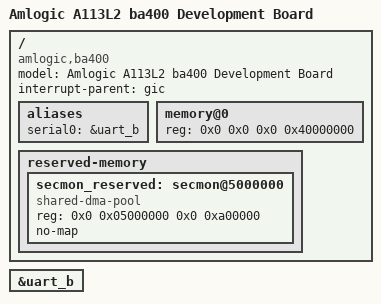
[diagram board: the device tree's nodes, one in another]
// SPDX-License-Identifier: (GPL-2.0+ OR MIT)
/*
 * Copyright (c) 2024 Amlogic, Inc. All rights reserved.
 */

/dts-v1/;

#include "amlogic-a4.dtsi"

/ {
	model = "Amlogic A113L2 ba400 Development Board";
	compatible = "amlogic,ba400", "amlogic,a4";
	interrupt-parent = <&gic>;
	#address-cells = <2>;
	#size-cells = <2>;

	aliases {
		serial0 = &uart_b;
	};

	memory@0 {
		device_type = "memory";
		reg = <0x0 0x0 0x0 0x40000000>;
	};

	reserved-memory {
		#address-cells = <2>;
		#size-cells = <2>;
		ranges;

		/* 10 MiB reserved for ARM Trusted Firmware */
		secmon_reserved: secmon@5000000 {
			compatible = "shared-dma-pool";
			reg = <0x0 0x05000000 0x0 0xa00000>;
			no-map;
		};
	};
};

&uart_b {
	status = "okay";
};
